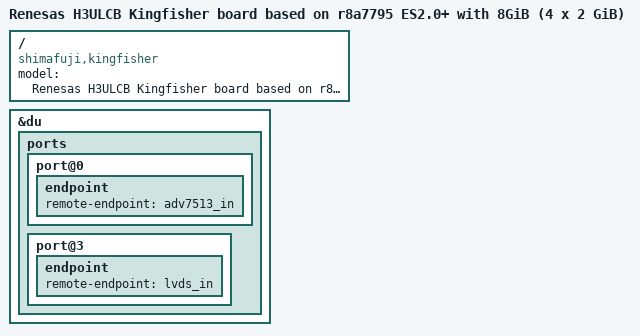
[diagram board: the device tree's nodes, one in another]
/*
 * Device Tree Source for the 8GB H3ULCB Kingfisher board
 *
 * Copyright (C) 2017 Renesas Electronics Corp.
 * Copyright (C) 2019 Cogent Embedded, Inc.
 *
 * This file is licensed under the terms of the GNU General Public License
 * version 2.  This program is licensed "as is" without any warranty of any
 * kind, whether express or implied.
 */

#include "r8a7795-h3ulcb-4x2g.dts"
#include "ulcb-kf.dtsi"

/ {
	model = "Renesas H3ULCB Kingfisher board based on r8a7795 ES2.0+ with 8GiB (4 x 2 GiB)";
	compatible = "shimafuji,kingfisher", "renesas,h3ulcb",
		     "renesas,r8a7795";
};

&du {
	ports {
		port@0 {
			endpoint {
				remote-endpoint = <&adv7513_in>;
			};
		};
		port@3 {
			endpoint {
				remote-endpoint = <&lvds_in>;
			};
		};
	};
};

/* use CN11 instead default CN29/CN48 (H3 only) */
//#include "ulcb-kf-cn11.dtsi"
